# MB9B560R register map
File version: 1.3
CPU: 
Registers are 8-bit, read-write, reset 0x0 unless marked. A register's access mark holds for its fields unless they carry their own. Offsets are from the block's base; [hi:lo] are bit positions; {n}, {i} and the like mark numbered series.

## LVD — Low-voltage Detection
Base 0x40035000
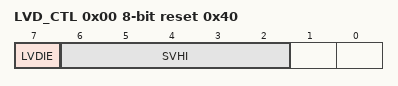
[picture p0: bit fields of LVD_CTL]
0x00 LVD_CTL reset 0x40 — Low-voltage Detection Voltage Control Register
  [7] LVDIE — Low-voltage detection interrupt enable bit
  [6:2] SVHI — Low-voltage detection interrupt voltage setting bits
0x04 LVD_STR ro — Low-voltage Detection Interrupt Factor Register
  [7] LVDIR — Low-voltage detection interrupt factor bit
0x08 LVD_CLR reset 0x80 — Low-voltage Detection Interrupt Factor Clear Register
  [7] LVDCL — Low-voltage detection interrupt factor clear bit
0x0C LVD_RLR 32-bit reset 0x1 — Low-voltage Detection Voltage Protection Register
  [31:0] LVDLCK — Low-voltage Detection Voltage Control Register protection bits
0x10 LVD_STR2 ro reset 0x40 — Low-voltage Detection Circuit Status Register
  [7] LVDIRDY — Low-voltage detection interrupt status flag

## DS — Low Power Consumption Mode
Base 0x40035100
0x04 RCK_CTL reset 0x1 — Sub Clock Control Register
  [0] RTCCKE — RTC clock control bit
0x700 PMD_CTL — RTC Mode Control Register
  [0] RTCE — RTC mode control bit
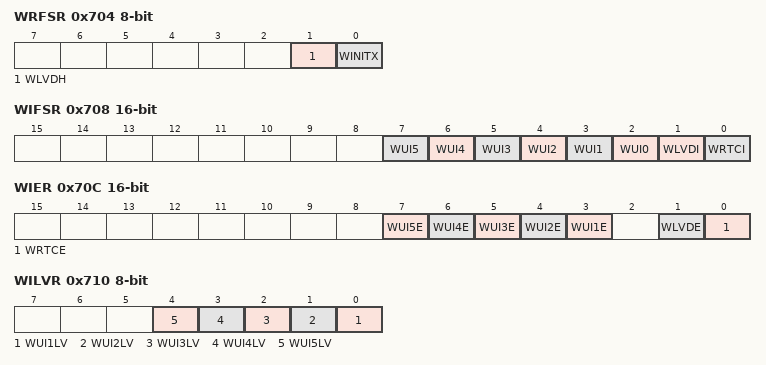
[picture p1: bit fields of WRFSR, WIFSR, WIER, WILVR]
0x704 WRFSR — Deep Standby Return Cause Register 1
  [1] WLVDH — Low-voltage detection reset return bit
  [0] WINITX — INITX pin input reset return bit
0x708 WIFSR 16-bit ro — Deep Standby Return Cause Register 2
  [n+2] WUI{n} (n=0..5) — WKUP pin input return bit {n}
  [1] WLVDI — LVD interrupt return bit
  [0] WRTCI — RTC interrupt return bit
0x70C WIER 16-bit — Deep Standby Return Enable Register
  [n+2] WUI{n}E (n=1..5) — WKUP pin input return enable bit {n}
  [1] WLVDE — LVD interrupt return enable bit
  [0] WRTCE — RTC interrupt return enable bit
0x710 WILVR — WKUP Pin Input Level Register
  [n-1] WUI{n}LV (n=1..5) — WKUP pin input level select bit {n}
0x714 DSRAMR — Deep Standby RAM Retention Register
  [1:0] SRAMR — On-chip SRAM retention control bits
{0x7FF+i} BUR{i:02} (i=1..16) — Backup Registers from {i}

## CRC — CRC Registers
Base 0x40039000
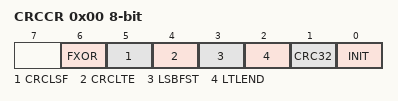
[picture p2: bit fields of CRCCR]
0x00 CRCCR — CRC Control Register
  [6] FXOR — Initialization bit
  [5] CRCLSF — Final XOR control bit
  [4] CRCLTE — CRC result bit-order setting bit
  [3] LSBFST — CRC result byte-order setting bit
  [2] LTLEND — Bit-order setting bit
  [1] CRC32 — Byte-order setting bit
  [0] INIT — CRC mode selection bit
0x04 CRCINIT 32-bit reset 0xFFFFFFFF — Initial Value Register
  [31:0] D — Initial value
0x08 CRCIN 32-bit — Input Data Register
  [31:0] D — Input data
0x0C CRCR 32-bit ro reset 0xFFFFFFFF — CRC Register
  [31:0] D — CRC Data

## WC — Watch Counter
Base 0x4003A000
0x00 WCRD ro — Watch Counter Read Register
  [5:0] CTR — Counter read bits
0x01 WCRL — Watch Counter Reload Register
  [5:0] RLC — Counter reload value setting bits
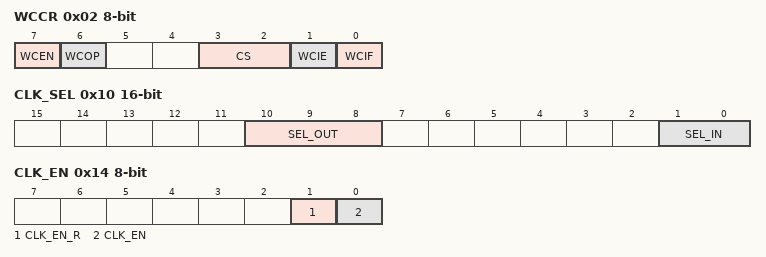
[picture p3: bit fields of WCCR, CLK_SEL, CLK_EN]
0x02 WCCR — Watch Counter Control Register
  [7] WCEN — Watch counter operation enable bit
  [6] WCOP ro — Watch counter operating state flag
  [3:2] CS — Count clock select bits
  [1] WCIE — Interrupt request enable bit
  [0] WCIF — Interrupt request flag bit
0x10 CLK_SEL 16-bit — Clock Selection Register
  [10:8] SEL_OUT — Output clock selection bit
  [1:0] SEL_IN — Input clock selection bit
0x14 CLK_EN — Division Clock Enable Register
  [1] CLK_EN_R — Division clock enable read bit
  [0] CLK_EN — Division clock enable bit

## LCR — Low-speed CR Prescaler
Base 0x4003C000
0x00 LCR_PRSLD — Low-speed CR Prescaler Control Register
  [5:0] LCR_PRSLD — Low-speed CR Prescaler Load

## PLL_CONTROL — Main PLL Control
Base 0x4003C800
0x00 SSCTL1 32-bit (reset mask 0x31)
0x04 SSCTL2 32-bit (reset mask 0x3FF)

## USBCLK — USB/Ethernet Clock
Base 0x40036000
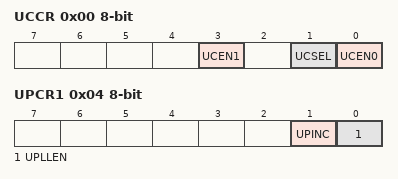
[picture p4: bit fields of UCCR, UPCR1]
0x00 UCCR — USB Clock Control Register
  [3] UCEN1 — USB1 clock output enable bit
  [1] UCSEL — USB clock selection bit
  [0] UCEN0 — USB0 clock output enable bit
0x04 UPCR1 — USB-PLL Control Register 1
  [1] UPINC — USB-PLL input clock selection bit
  [0] UPLLEN — USB-PLL oscillation enable bit
0x08 UPCR2 — USB-PLL Control Register 2
  [2:0] UPOWT — USB-PLL oscillation stabilization wait time setting bit
0x0C UPCR3 — USB-PLL Control Register 3
  [4:0] UPLLK — Frequency division ratio (K) setting bit of the USB-PLL clock
0x10 UPCR4 reset 0x3B — USB-PLL Control Register 4
  [6:0] UPLLN — Frequency division ratio (N) setting bit of the USB-PLL clock
0x14 UP_STR ro — USB-PLL Status Register
  [0] UPRDY — USB-PLL oscillation stabilization bit
0x18 UPINT_ENR — USB-PLL Interrupt Factor Enable Register
  [0] UPCSE — USB-PLL oscillation stabilization wait complete interrupt enable bit
0x1C UPINT_CLR wo — USB-PLL Interrupt Factor Clear Register
  [0] UPCSC — USB-PLL oscillation stabilization interrupt factor clear bit
0x20 UPINT_STR ro — USB-PLL Interrupt Factor Status Register
  [0] UPCSI — USB-PLL interrupt factor status bit
0x24 UPCR5 reset 0x4 — USB-PLL Control Register 5
  [3:0] UPLLM — Frequency division ratio (M) setting bit of the USB-PLL clock
0x30 USBEN0 — USB0 Enable Register
  [0] USBEN0 — USB0 enable bit
0x34 USBEN1 — USB1 Enable Register
  [0] USBEN1 — USB1 enable bit

## DMAC — DMAC Registers
Base 0x40060000
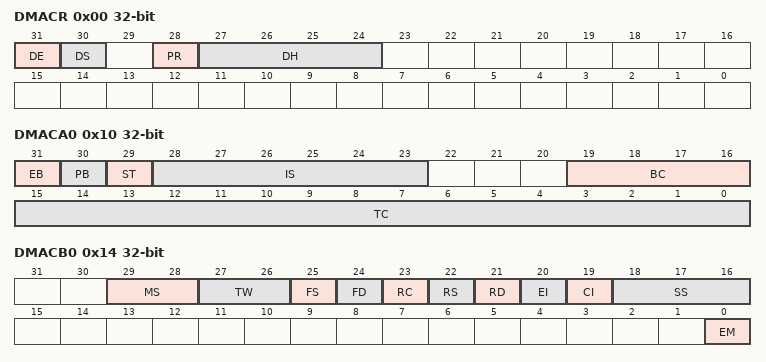
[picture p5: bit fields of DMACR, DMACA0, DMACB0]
0x00 DMACR 32-bit — Entire DMAC Configuration Register
  [31] DE — DMA Enable (all-channel operation enable bit)
  [30] DS — DMA Stop
  [28] PR — Priority Rotation
  [27:24] DH — DMA Halt (All-channel pause bit)
0x10 DMACA0 32-bit — Configuration A Register
  [31] EB — Enable bit (individual-channel operation enable bit)
  [30] PB — Pause bit (individual-channel pause bit)
  [29] ST — Software Trigger
  [28:23] IS — Input Select
  [19:16] BC — Block Count
  [15:0] TC — Transfer Count
0x14 DMACB0 32-bit — Configuration B Register
  [29:28] MS — Mode Select
  [27:26] TW — Transfer Width
  [25] FS — Fixed Source
  [24] FD — Fixed Destination
  [23] RC — Reload Count (BC/TC reload)
  [22] RS — Reload Source
  [21] RD — Reload Destination
  [20] EI — Error Interrupt (unsuccessful transfer completion interrupt enable)
  [19] CI — Completion Interrupt (successful transfer completion interrupt enable)
  [18:16] SS — Stop Status (stop status notification)
  [0] EM — Enable bit Mask (EB bit clear mask)
0x18 DMACSA0 32-bit — Transfer Source Address Register
0x1C DMACDA0 32-bit — Transfer Destination Address Register
{0x10+0x10*i} DMACA{i} 32-bit reset not defined (i=1..7) — Configuration A Register {i}
{0x14+0x10*i} DMACB{i} 32-bit reset not defined (i=1..7) — Configuration B Register {i}
{0x18+0x10*i} DMACSA{i} 32-bit reset not defined (i=1..7) — Transfer Source Address Register {i}
{0x1C+0x10*i} DMACDA{i} 32-bit reset not defined (i=1..7) — Transfer Destination Address Register {i}

## DSTC — DSTC registers
Base 0x40061000
0x00 DESTP 32-bit — Descriptor top address Register
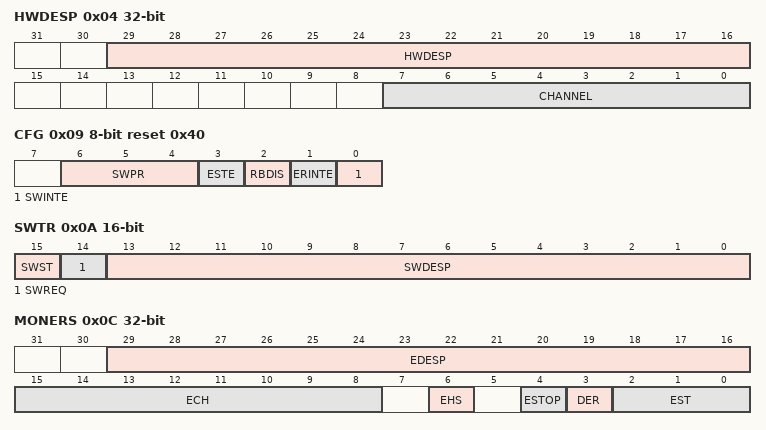
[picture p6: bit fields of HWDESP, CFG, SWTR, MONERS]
0x04 HWDESP 32-bit — Hardware DES pointer Register
  [29:16] HWDESP, [7:0] CHANNEL
0x08 CMD reset 0x1 — Command Register
0x09 CFG reset 0x40 — Configuration Register
  [6:4] SWPR — Software transfer priority
  [3] ESTE — Error stop enable
  [2] RBDIS — Read skip buffer disable
  [1] ERINTE — Error interrupt enable
  [0] SWINTE — Software interrupt enable
0x0A SWTR 16-bit — Software trigger Register
  [15] SWST ro — Software status
  [14] SWREQ ro — Software request
  [13:0] SWDESP — Software DES pointer
0x0C MONERS 32-bit
  [29:16] EDESP ro — Error DES pointer
  [15:8] ECH ro — Error hardware channel
  [6] EHS ro — Error hardware software
  [4] ESTOP ro — Error stop
  [3] DER ro — Double error
  [2:0] EST ro — Error status
0x10 DREQENB0 32-bit — DMA request enable Register 0
{0x10+4i} DREQENB{i} 32-bit reset not defined (i=1..7) — DMA request enable Register {i}
0x30 HWINT0 32-bit — Hardware transfer interrupt Register 0
{0x30+4i} HWINT{i} 32-bit reset not defined (i=1..7) — Hardware transfer interrupt Register {i}
0x50 HWINTCLR0 32-bit — Hardware transfer interrupt clear Register 0
{0x50+4i} HWINTCLR{i} 32-bit reset not defined (i=1..7) — Hardware transfer interrupt clear Register {i}
0x70 DQMSK0 32-bit — DMA request mask Register 0
{0x70+4i} DQMSK{i} 32-bit reset not defined (i=1..7) — DMA request mask Register {i}
0x90 DQMSKCLR0 32-bit — DMA request mask clear Register 0
{0x90+4i} DQMSKCLR{i} 32-bit reset not defined (i=1..7) — DMA request mask clear Register {i}

## CANPRES — CAN Prescaler Register
Base 0x40037000
0x00 CANPRE reset 0xB — CAN Prescaler Register
  [3:0] CANPRE — CAN prescaler setting bits

## SDIF — SD Card Interface
Base 0x4006E000
0x00 DUMMY 32-bit reset not defined
